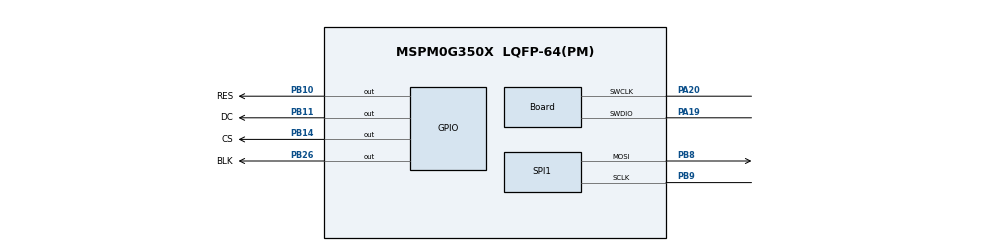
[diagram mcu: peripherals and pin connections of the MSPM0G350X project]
/**
 * @cliArgs --device "MSPM0G350X" --part "Default" --package "LQFP-64(PM)" --product "mspm0_sdk@2.10.00.04"
 * @versions {"tool":"1.26.2+4477"}
 */

/**
 * Import the modules used in this configuration.
 */
const Board  = scripting.addModule("/ti/driverlib/Board");
const GPIO   = scripting.addModule("/ti/driverlib/GPIO", {}, false);
const GPIO1  = GPIO.addInstance();
const PWM    = scripting.addModule("/ti/driverlib/PWM", {}, false);
const PWM1   = PWM.addInstance();
const PWM2   = PWM.addInstance();
const SPI    = scripting.addModule("/ti/driverlib/SPI", {}, false);
const SPI1   = SPI.addInstance();
const SYSCTL = scripting.addModule("/ti/driverlib/SYSCTL");

/**
 * Write custom configuration values to the imported modules.
 */
Board.peripheral.swclkPin.$assign = "PA20";
Board.peripheral.swdioPin.$assign = "PA19";

GPIO1.$name                          = "GPIO_LCD";
GPIO1.associatedPins.create(4);
GPIO1.associatedPins[0].$name        = "CS";
GPIO1.associatedPins[0].initialValue = "SET";
GPIO1.associatedPins[0].pin.$assign  = "PB14";
GPIO1.associatedPins[1].$name        = "DC";
GPIO1.associatedPins[1].initialValue = "SET";
GPIO1.associatedPins[1].pin.$assign  = "PB11";
GPIO1.associatedPins[2].$name        = "RES";
GPIO1.associatedPins[2].initialValue = "SET";
GPIO1.associatedPins[2].pin.$assign  = "PB10";
GPIO1.associatedPins[3].$name        = "BLK";
GPIO1.associatedPins[3].initialValue = "SET";
GPIO1.associatedPins[3].pin.$assign  = "PB26";

PWM1.$name                              = "MOTOR_PWM";
PWM1.timerCount                         = 3200;
PWM1.PWM_CHANNEL_0.$name                = "ti_driverlib_pwm_PWMTimerCC0";
PWM1.PWM_CHANNEL_1.$name                = "ti_driverlib_pwm_PWMTimerCC1";
PWM1.ccp0PinConfig.$name                = "ti_driverlib_gpio_GPIOPinGeneric0";
PWM1.ccp0PinConfig.direction            = scripting.forceWrite("OUTPUT");
PWM1.ccp0PinConfig.hideOutputInversion  = scripting.forceWrite(false);
PWM1.ccp0PinConfig.onlyInternalResistor = scripting.forceWrite(false);
PWM1.ccp0PinConfig.passedPeripheralType = scripting.forceWrite("Digital");
PWM1.ccp1PinConfig.$name                = "ti_driverlib_gpio_GPIOPinGeneric1";
PWM1.ccp1PinConfig.direction            = scripting.forceWrite("OUTPUT");
PWM1.ccp1PinConfig.hideOutputInversion  = scripting.forceWrite(false);
PWM1.ccp1PinConfig.onlyInternalResistor = scripting.forceWrite(false);
PWM1.ccp1PinConfig.passedPeripheralType = scripting.forceWrite("Digital");

PWM2.$name                              = "PWM_0";
PWM2.PWM_CHANNEL_0.$name                = "ti_driverlib_pwm_PWMTimerCC2";
PWM2.PWM_CHANNEL_1.$name                = "ti_driverlib_pwm_PWMTimerCC3";
PWM2.ccp0PinConfig.$name                = "ti_driverlib_gpio_GPIOPinGeneric2";
PWM2.ccp0PinConfig.direction            = scripting.forceWrite("OUTPUT");
PWM2.ccp0PinConfig.hideOutputInversion  = scripting.forceWrite(false);
PWM2.ccp0PinConfig.onlyInternalResistor = scripting.forceWrite(false);
PWM2.ccp0PinConfig.passedPeripheralType = scripting.forceWrite("Digital");
PWM2.ccp1PinConfig.$name                = "ti_driverlib_gpio_GPIOPinGeneric3";
PWM2.ccp1PinConfig.direction            = scripting.forceWrite("OUTPUT");
PWM2.ccp1PinConfig.hideOutputInversion  = scripting.forceWrite(false);
PWM2.ccp1PinConfig.onlyInternalResistor = scripting.forceWrite(false);
PWM2.ccp1PinConfig.passedPeripheralType = scripting.forceWrite("Digital");

SPI1.$name                              = "SPI_LCD";
SPI1.chipSelect                         = [];
SPI1.frameFormat                        = "MOTO3";
SPI1.targetBitRate                      = 16000000;
SPI1.sclkPinConfig.$name                = "ti_driverlib_gpio_GPIOPinGeneric4";
SPI1.sclkPinConfig.direction            = scripting.forceWrite("OUTPUT");
SPI1.sclkPinConfig.onlyInternalResistor = scripting.forceWrite(false);
SPI1.sclkPinConfig.passedPeripheralType = scripting.forceWrite("Digital");
SPI1.mosiPinConfig.$name                = "ti_driverlib_gpio_GPIOPinGeneric5";
SPI1.mosiPinConfig.direction            = scripting.forceWrite("OUTPUT");
SPI1.mosiPinConfig.hideOutputInversion  = scripting.forceWrite(false);
SPI1.mosiPinConfig.onlyInternalResistor = scripting.forceWrite(false);
SPI1.mosiPinConfig.passedPeripheralType = scripting.forceWrite("Digital");
SPI1.misoPinConfig.$name                = "ti_driverlib_gpio_GPIOPinGeneric6";
SPI1.misoPinConfig.onlyInternalResistor = scripting.forceWrite(false);
SPI1.misoPinConfig.passedPeripheralType = scripting.forceWrite("Digital");
SPI1.peripheral.sclkPin.$assign         = "PB9";
SPI1.peripheral.mosiPin.$assign         = "PB8";

SYSCTL.forceDefaultClkConfig = true;

/**
 * Pinmux solution for unlocked pins/peripherals. This ensures that minor changes to the automatic solver in a future
 * version of the tool will not impact the pinmux you originally saw.  These lines can be completely deleted in order to
 * re-solve from scratch.
 */
Board.peripheral.$suggestSolution        = "DEBUGSS";
PWM1.peripheral.$suggestSolution         = "TIMA1";
PWM1.peripheral.ccp0Pin.$suggestSolution = "PA10";
PWM1.peripheral.ccp1Pin.$suggestSolution = "PA11";
PWM2.peripheral.$suggestSolution         = "TIMA0";
PWM2.peripheral.ccp0Pin.$suggestSolution = "PA0";
PWM2.peripheral.ccp1Pin.$suggestSolution = "PA1";
SPI1.peripheral.$suggestSolution         = "SPI1";
SPI1.peripheral.misoPin.$suggestSolution = "PA16";
SYSCTL.peripheral.$suggestSolution       = "SYSCTL";
